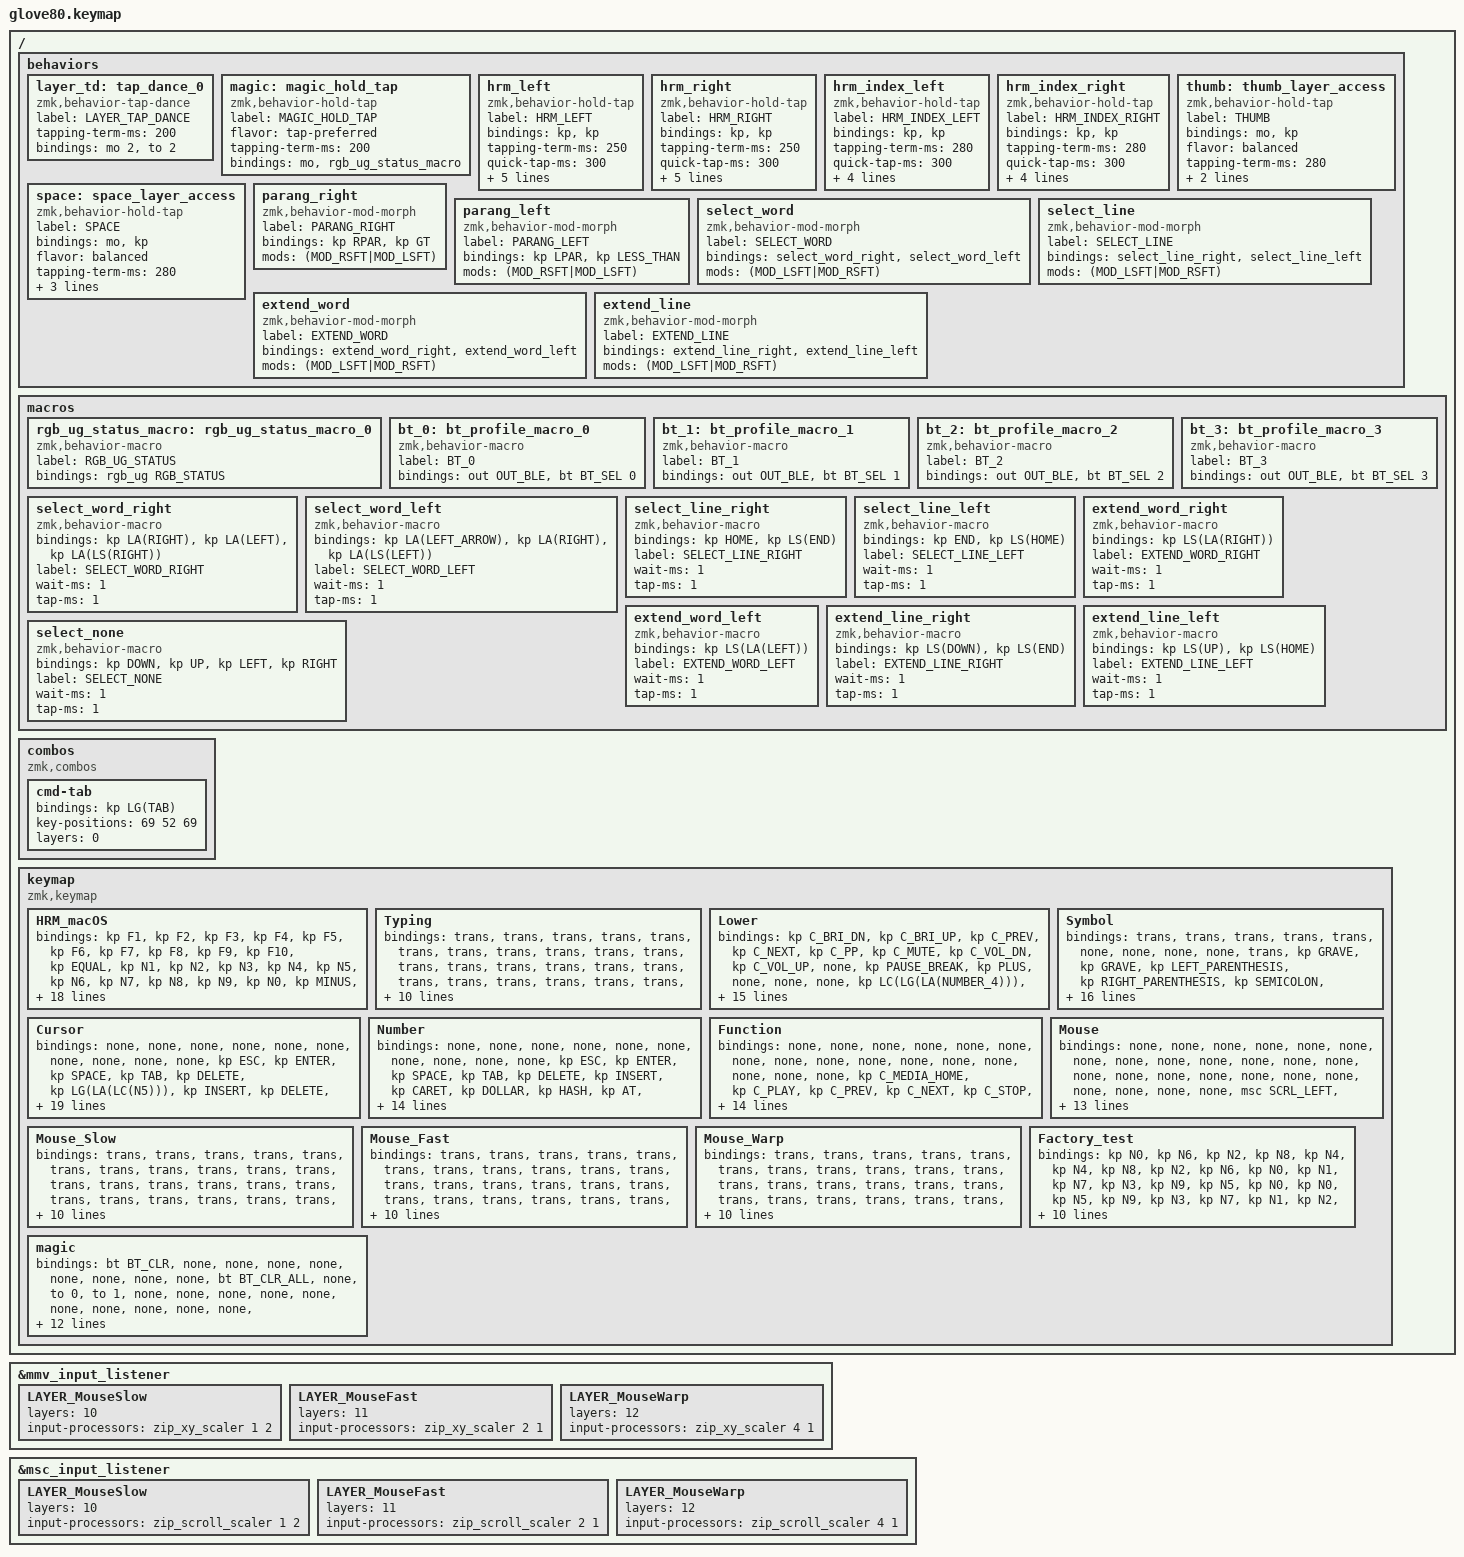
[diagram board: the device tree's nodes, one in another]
/*
 * Copyright (c) 2020 The ZMK Contributors
 *
 * SPDX-License-Identifier: MIT
 */

#include <input/processors.dtsi>
#include <behaviors.dtsi>
#include <dt-bindings/zmk/bt.h>
#include <dt-bindings/zmk/keys.h>
#include <dt-bindings/zmk/outputs.h>
#include <dt-bindings/zmk/pointing.h>
#include <dt-bindings/zmk/rgb.h>

#define HYPER LC(LS(LG(LALT)))

// layers

#define DEFAULT 0
#define LOWER 1
#define MAGIC 2
#define FACTORY_TEST 3
#define LAYER_MouseSlow 10
#define LAYER_MouseFast 11
#define LAYER_MouseWarp 12

/* Input Listeners */

&mmv_input_listener {
    // LAYER_MouseSlow
    // 

    LAYER_MouseSlow {
        layers = <10>;
        input-processors = <&zip_xy_scaler 1 2>;
    };

    // LAYER_MouseFast

    LAYER_MouseFast {
        layers = <11>;
        input-processors = <&zip_xy_scaler 2 1>;
    };

    // LAYER_MouseWarp

    LAYER_MouseWarp {
        layers = <12>;
        input-processors = <&zip_xy_scaler 4 1>;
    };
};

&msc_input_listener {
    // LAYER_MouseSlow
    // 

    LAYER_MouseSlow {
        layers = <10>;
        input-processors = <&zip_scroll_scaler 1 2>;
    };

    // LAYER_MouseFast

    LAYER_MouseFast {
        layers = <11>;
        input-processors = <&zip_scroll_scaler 2 1>;
    };

    // LAYER_MouseWarp

    LAYER_MouseWarp {
        layers = <12>;
        input-processors = <&zip_scroll_scaler 4 1>;
    };
};

/ {
    behaviors {
        // For the "layer" key, it'd nice to be able to use it as either a shift or a toggle.
        // Configure it as a tap dance, so the first tap (or hold) is a &mo and the second tap is a &to

        layer_td: tap_dance_0 {
            compatible = "zmk,behavior-tap-dance";
            label = "LAYER_TAP_DANCE";
            #binding-cells = <0>;
            tapping-term-ms = <200>;
            bindings = <&mo 2>, <&to 2>;
        };

        magic: magic_hold_tap {
            compatible = "zmk,behavior-hold-tap";
            label = "MAGIC_HOLD_TAP";
            #binding-cells = <2>;
            flavor = "tap-preferred";
            tapping-term-ms = <200>;
            bindings = <&mo>, <&rgb_ug_status_macro>;
        };

        hrm_left: hrm_left {
            compatible = "zmk,behavior-hold-tap";
            label = "HRM_LEFT";
            bindings = <&kp>, <&kp>;

            #binding-cells = <2>;
            tapping-term-ms = <250>;
            quick-tap-ms = <300>;
            flavor = "tap-preferred";
            hold-trigger-on-release;
            hold-trigger-key-positions = <5 6 7 8 9 16 17 18 19 20 21 28 29 30 31 32 33 40 41 42 43 44 45 55 56 57 58 59 60 61 62 63 72 73 74 75 76 77 78 79 52 53 54 69 70 71>;
            require-prior-idle-ms = <250>;
        };

        hrm_right: hrm_right {
            compatible = "zmk,behavior-hold-tap";
            label = "HRM_RIGHT";
            bindings = <&kp>, <&kp>;

            #binding-cells = <2>;
            tapping-term-ms = <250>;
            quick-tap-ms = <300>;
            flavor = "tap-preferred";
            hold-trigger-on-release;
            hold-trigger-key-positions = <0 1 2 3 4 10 11 12 13 14 15 22 23 24 25 26 27 34 35 36 37 38 39 46 47 48 49 50 51 52 53 54 55 56 57 64 65 66 67 68 69 70 71 72 73 74>;
            require-prior-idle-ms = <250>;
        };

        hrm_index_left: hrm_index_left {
            compatible = "zmk,behavior-hold-tap";
            label = "HRM_INDEX_LEFT";
            bindings = <&kp>, <&kp>;

            #binding-cells = <2>;
            tapping-term-ms = <280>;
            quick-tap-ms = <300>;
            flavor = "tap-preferred";
            hold-trigger-key-positions = <5 6 7 8 9 16 17 18 19 20 21 28 29 30 31 32 33 40 41 42 43 44 45 55 56 57 58 59 60 61 62 63 72 73 74 75 76 77 78 79 52 53 54 69 70 71>;
            require-prior-idle-ms = <250>;
        };

        hrm_index_right: hrm_index_right {
            compatible = "zmk,behavior-hold-tap";
            label = "HRM_INDEX_RIGHT";
            bindings = <&kp>, <&kp>;

            #binding-cells = <2>;
            tapping-term-ms = <280>;
            quick-tap-ms = <300>;
            flavor = "tap-preferred";
            hold-trigger-key-positions = <0 1 2 3 4 10 11 12 13 14 15 22 23 24 25 26 27 34 35 36 37 38 39 46 47 48 49 50 51 52 53 54 55 56 57 64 65 66 67 68 69 70 71 72 73 74>;
            require-prior-idle-ms = <250>;
        };

        thumb: thumb_layer_access {
            compatible = "zmk,behavior-hold-tap";
            label = "THUMB";
            bindings = <&mo>, <&kp>;

            #binding-cells = <2>;
            flavor = "balanced";
            tapping-term-ms = <280>;
            quick-tap-ms = <110>;
            require-prior-idle-ms = <170>;
        };

        space: space_layer_access {
            compatible = "zmk,behavior-hold-tap";
            label = "SPACE";
            bindings = <&mo>, <&kp>;

            #binding-cells = <2>;
            flavor = "balanced";
            tapping-term-ms = <280>;
            quick-tap-ms = <175>;
            require-prior-idle-ms = <170>;
            hold-trigger-on-release;
        };

        parang_right: parang_right {
            compatible = "zmk,behavior-mod-morph";
            label = "PARANG_RIGHT";
            bindings = <&kp RPAR>, <&kp GT>;

            #binding-cells = <0>;
            mods = <(MOD_RSFT|MOD_LSFT)>;
        };

        parang_left: parang_left {
            compatible = "zmk,behavior-mod-morph";
            label = "PARANG_LEFT";
            bindings = <&kp LPAR>, <&kp LESS_THAN>;

            #binding-cells = <0>;
            mods = <(MOD_RSFT|MOD_LSFT)>;
        };

        select_word: select_word {
            compatible = "zmk,behavior-mod-morph";
            label = "SELECT_WORD";
            #binding-cells = <0>;
            bindings = <&select_word_right>, <&select_word_left>;

            mods = <(MOD_LSFT|MOD_RSFT)>;
        };

        select_line: select_line {
            compatible = "zmk,behavior-mod-morph";
            label = "SELECT_LINE";
            bindings = <&select_line_right>, <&select_line_left>;

            #binding-cells = <0>;
            mods = <(MOD_LSFT|MOD_RSFT)>;
        };

        extend_word: extend_word {
            compatible = "zmk,behavior-mod-morph";
            label = "EXTEND_WORD";
            bindings = <&extend_word_right>, <&extend_word_left>;

            #binding-cells = <0>;
            mods = <(MOD_LSFT|MOD_RSFT)>;
        };

        extend_line: extend_line {
            compatible = "zmk,behavior-mod-morph";
            label = "EXTEND_LINE";
            bindings = <&extend_line_right>, <&extend_line_left>;

            #binding-cells = <0>;
            mods = <(MOD_LSFT|MOD_RSFT)>;
        };
    };

    macros {
        rgb_ug_status_macro: rgb_ug_status_macro_0 {
            label = "RGB_UG_STATUS";
            compatible = "zmk,behavior-macro";
            #binding-cells = <0>;
            bindings = <&rgb_ug RGB_STATUS>;
        };

        bt_0: bt_profile_macro_0 {
            label = "BT_0";
            compatible = "zmk,behavior-macro";
            #binding-cells = <0>;
            bindings = <&out OUT_BLE &bt BT_SEL 0>;
        };

        bt_1: bt_profile_macro_1 {
            label = "BT_1";
            compatible = "zmk,behavior-macro";
            #binding-cells = <0>;
            bindings = <&out OUT_BLE &bt BT_SEL 1>;
        };

        bt_2: bt_profile_macro_2 {
            label = "BT_2";
            compatible = "zmk,behavior-macro";
            #binding-cells = <0>;
            bindings = <&out OUT_BLE &bt BT_SEL 2>;
        };

        bt_3: bt_profile_macro_3 {
            label = "BT_3";
            compatible = "zmk,behavior-macro";
            #binding-cells = <0>;
            bindings = <&out OUT_BLE &bt BT_SEL 3>;
        };

        select_word_right: select_word_right {
            compatible = "zmk,behavior-macro";
            #binding-cells = <0>;
            bindings = <&kp LA(RIGHT) &kp LA(LEFT) &kp LA(LS(RIGHT))>;
            label = "SELECT_WORD_RIGHT";
            wait-ms = <1>;
            tap-ms = <1>;
        };

        select_word_left: select_word_left {
            compatible = "zmk,behavior-macro";
            #binding-cells = <0>;
            bindings = <&kp LA(LEFT_ARROW) &kp LA(RIGHT) &kp LA(LS(LEFT))>;
            label = "SELECT_WORD_LEFT";
            wait-ms = <1>;
            tap-ms = <1>;
        };

        select_line_right: select_line_right {
            compatible = "zmk,behavior-macro";
            #binding-cells = <0>;
            bindings = <&kp HOME &kp LS(END)>;
            label = "SELECT_LINE_RIGHT";
            wait-ms = <1>;
            tap-ms = <1>;
        };

        select_line_left: select_line_left {
            compatible = "zmk,behavior-macro";
            #binding-cells = <0>;
            bindings = <&kp END &kp LS(HOME)>;
            label = "SELECT_LINE_LEFT";
            wait-ms = <1>;
            tap-ms = <1>;
        };

        extend_word_right: extend_word_right {
            compatible = "zmk,behavior-macro";
            #binding-cells = <0>;
            bindings = <&kp LS(LA(RIGHT))>;
            label = "EXTEND_WORD_RIGHT";
            wait-ms = <1>;
            tap-ms = <1>;
        };

        extend_word_left: extend_word_left {
            compatible = "zmk,behavior-macro";
            #binding-cells = <0>;
            bindings = <&kp LS(LA(LEFT))>;
            label = "EXTEND_WORD_LEFT";
            wait-ms = <1>;
            tap-ms = <1>;
        };

        extend_line_right: extend_line_right {
            compatible = "zmk,behavior-macro";
            #binding-cells = <0>;
            bindings = <&kp LS(DOWN) &kp LS(END)>;
            label = "EXTEND_LINE_RIGHT";
            wait-ms = <1>;
            tap-ms = <1>;
        };

        extend_line_left: extend_line_left {
            compatible = "zmk,behavior-macro";
            #binding-cells = <0>;
            bindings = <&kp LS(UP) &kp LS(HOME)>;
            label = "EXTEND_LINE_LEFT";
            wait-ms = <1>;
            tap-ms = <1>;
        };

        select_none: select_none {
            compatible = "zmk,behavior-macro";
            #binding-cells = <0>;
            bindings = <&kp DOWN &kp UP &kp LEFT &kp RIGHT>;
            label = "SELECT_NONE";
            wait-ms = <1>;
            tap-ms = <1>;
        };
    };

    combos {
        compatible = "zmk,combos";

        cmd-tab {
            bindings = <&kp LG(TAB)>;
            key-positions = <69 52 69>;
            layers = <0>;
        };
    };

    keymap {
        compatible = "zmk,keymap";

        HRM_macOS {
            // ---------------------------------------------------------------------------------------------------------------------------------
            // |  F1   |  F2 |  F3 |  F4  |  F5  |                                                               |  F6   |  F7   |  F8  |   F9  |  F10 |
            // |  =    |  1  |  2  |  3   |  4   |  5   |                                                 |  6   |   7   |   8   |  9   |   0   |   -  |
            // |  TAB  |  Q  |  W  |  E   |  R   |  T   |                                                 |  Y   |   U   |   I   |  O   |   P   |   \  |
            // |  ESC  |  A  |  S  |  D   |  F   |  G   |                                                 |  H   |   J   |   K   |  L   |   ;   |   '  |
            // |   `   |  Z  |  X  |  C   |  V   |  B   | LSHFT | LCTRL | LOWER | | LGUI  | RCTRL | RSHFT |  N   |   M   |   ,   |  .   |   /   | PGUP |
            // | MAGIC | HOME| END | LEFT | RIGHT|      | BSPC  | DEL   | LALT  | | RALT  | RET   | SPACE |      |  UP   | DOWN  |  [   |   ]   | PGDN |

            bindings = <
&kp F1       &kp F2             &kp F3             &kp F4             &kp F5                                                                                                                                                                              &kp F6                    &kp F7             &kp F8             &kp F9                      &kp F10
&kp EQUAL    &kp N1             &kp N2             &kp N3             &kp N4                   &kp N5                                                                                                                        &kp N6                       &kp N7                    &kp N8             &kp N9             &kp N0                      &kp MINUS
&kp TAB      &kp Q              &kp W              &kp E              &kp R                    &kp T                                                                                                                         &kp Y                        &kp U                     &kp I              &kp O              &kp P                       &kp BSLH
&kp ESCAPE   &hrm_left LCTRL A  &hrm_right LALT S  &hrm_left LGUI D   &hrm_index_left LSHFT F  &kp G                                                                                                                         &kp H                        &hrm_index_right RSHFT J  &hrm_right RGUI K  &hrm_right LALT L  &hrm_right RCTRL SEMICOLON  &kp SQT
&kp GRAVE    &kp Z              &kp X              &kp C              &kp V                    &hrm_left LC(LEFT_ALT) B  &thumb 6 ESCAPE     &caps_word       &layer_td       &layer_td      &kp CAPS        &kp ENTER       &hrm_right RA(LEFT_SHIFT) N  &kp M                     &kp COMMA          &kp DOT            &kp FSLH                    &kp PAGE_UP
&magic 12 0  &parang_left       &kp LEFT_BRACKET   &kp RIGHT_BRACKET  &parang_right                                      &thumb 4 BACKSPACE  &thumb 5 DELETE  &thumb 2 LG(S)  &kp BACKSPACE  &thumb 7 ENTER  &space 3 SPACE                               &kp LEFT                  &kp DOWN           &kp UP_ARROW       &kp RIGHT                   &kp PAGE_DOWN
            >;
        };

        Typing {
            bindings = <
&trans  &trans  &trans  &trans  &trans                                                                  &trans  &trans  &trans  &trans         &trans
&trans  &trans  &trans  &trans  &trans  &trans                                                  &trans  &trans  &trans  &trans  &trans         &trans
&trans  &trans  &trans  &trans  &trans  &trans                                                  &trans  &trans  &trans  &trans  &trans         &trans
&trans  &kp A   &kp S   &kp D   &kp F   &trans                                                  &trans  &kp J   &kp K   &kp L   &kp SEMICOLON  &trans
&trans  &trans  &trans  &trans  &trans  &trans  &trans  &trans  &trans  &trans  &trans  &trans  &trans  &trans  &trans  &trans  &trans         &trans
&trans  &trans  &trans  &trans  &trans          &trans  &trans  &trans  &trans  &trans  &trans          &trans  &trans  &trans  &trans         &trans
            >;
        };

        Lower {
            bindings = <
&kp C_BRI_DN  &kp C_BRI_UP  &kp C_PREV  &kp C_NEXT  &kp C_PP                                                                                              &kp C_MUTE  &kp C_VOL_DN  &kp C_VOL_UP   &none            &kp PAUSE_BREAK
&kp PLUS      &none         &none       &none       &kp LC(LG(LA(NUMBER_4)))  &kp LG(LA(LC(N5)))                                               &kp LPAR   &kp KP_NUM  &kp KP_EQUAL  &kp KP_DIVIDE  &kp KP_MULTIPLY  &kp PSCRN
&kp TAB       &none         &none       &kp UP      &none                     &kp LS(LA(LG(LC(D))))                                            &kp RPAR   &kp KP_N7   &kp KP_N8     &kp KP_N9      &kp KP_MINUS     &kp SLCK
&kp ESCAPE    &none         &kp LEFT    &kp DOWN    &kp RIGHT                 &none                                                            &kp PRCNT  &kp KP_N4   &kp KP_N5     &kp KP_N6      &kp KP_PLUS      &none
&kp TILDE     &kp K_CMENU   &kp F1      &kp F2      &kp F5                    &none                  &to 6  &none  &none  &none  &none  &none  &kp COMMA  &kp KP_N1   &kp KP_N2     &kp KP_N3      &kp KP_ENTER     &trans
&trans        &kp CAPS      &kp F10     &kp F11     &kp F12                                          &to 4  &to 5  &none  &none  &to 7  &to 3             &kp KP_N0   &kp KP_N0     &kp KP_DOT     &kp KP_ENTER     &trans
            >;
        };

        Symbol {
            bindings = <
&trans           &trans         &trans                &trans                 &trans                                                                                                    &none          &none        &none          &none          &trans
&kp GRAVE        &kp GRAVE      &kp LEFT_PARENTHESIS  &kp RIGHT_PARENTHESIS  &kp SEMICOLON     &kp COMMA                                                                &none          &none          &none        &none          &none          &none
&kp EXCLAMATION  &kp LBRC       &kp SQT               &kp DOUBLE_QUOTES      &kp RBRC          &kp QUESTION                                                             &kp SEMICOLON  &kp RSHFT      &kp RGUI     &kp RALT       &kp RCTRL      &none
&kp HASH         &kp CARET      &kp EQUAL             &kp UNDERSCORE         &kp DOLLAR        &kp ASTERISK                                                             &kp DOT        &kp BACKSPACE  &kp TAB      &kp SPACE      &kp ENTER      &none
&kp AT           &kp LESS_THAN  &kp PIPE              &kp MINUS              &kp GREATER_THAN  &kp FSLH      &kp BSLH     &kp DOT    &kp ASTERISK  &to 0  &none  &none  &kp RG(SPACE)  &kp DEL        &kp LS(TAB)  &kp RC(SPACE)  &kp RA(ENTER)  &none
&kp TILDE        &kp AMPERSAND  &kp LBKT              &kp RBKT               &kp PLUS                        &kp PERCENT  &kp COLON  &kp SEMI      &none  &none  &none                 &trans         &trans       &trans         &trans         &kp RG(SPACE)
            >;
        };

        Cursor {
            bindings = <
&none           &none            &none          &none         &none                                                                                                                                 &none          &none            &none          &none            &none
&kp ESC         &kp ENTER        &kp SPACE      &kp TAB       &kp DELETE     &kp LG(LA(LC(N5)))                                                                                         &kp INSERT  &kp DELETE     &kp TAB          &kp SPACE      &kp ENTER        &kp ESC
&kp CAPSLOCK    &sk RIGHT_SHIFT  &kp LG(LS(Z))  &kp LG(Z)     &kp BACKSPACE  &kp LG(X)                                                                                                  &kp RG(X)   &kp BACKSPACE  &kp RG(Z)        &kp RG(RS(Z))  &sk RIGHT_SHIFT  &kp RG(K)
&sk LEFT_SHIFT  &kp LCTRL        &kp LALT       &kp LGUI      &kp LSHFT      &kp LG(C)                                                                                                  &kp LEFT    &kp DOWN       &kp UP_ARROW     &kp RIGHT      &none            &kp RG(L)
&kp LG(J)       &kp LG(A)        &select_line   &select_word  &kp LG(F)      &kp LG(V)           &kp LS(LA(LG(V)))  &kp LC(TAB)  &to 0        &select_none  &extend_line  &extend_word  &kp HOME    &kp PAGE_DOWN  &kp RG(PAGE_UP)  &kp END        &kp LA(RG(F))    &kp RG(J)
&kp LA(LG(F))   &kp LG(LS(G))    &extend_line   &extend_word  &kp LG(G)                          &none              &kp LG(TAB)  &kp LA(TAB)  &kp RG(A)     &select_line  &select_word              &kp HOME       &kp PAGE_DOWN    &kp PG_UP      &kp END          &kp RC(RG(SPACE))
            >;
        };

        Number {
            bindings = <
&none           &none      &none          &none         &none                                                                                                     &none       &none     &none   &none            &none
&kp ESC         &kp ENTER  &kp SPACE      &kp TAB       &kp DELETE     &kp INSERT                                                                   &kp CARET     &kp DOLLAR  &kp HASH  &kp AT  &kp EXCLAMATION  &kp PIPE
&none           &sk LSHFT  &kp LG(LS(Z))  &kp LG(Z)     &kp BACKSPACE  &kp A                                                                        &kp PERCENT   &kp N7      &kp N8    &kp N9  &kp COLON        &kp K
&kp LG(ESCAPE)  &kp LCTRL  &kp LALT       &kp LGUI      &kp LSHIFT     &kp B                                                                        &kp PLUS      &kp N4      &kp N5    &kp N6  &kp MINUS        &kp J
&none           &kp LG(A)  &select_line   &select_word  &kp BACKSPACE  &kp D       &kp E  &kp F  &to 0  &kp LESS_THAN  &kp GREATER_THAN  &kp EQUAL  &kp ASTERISK  &kp N1      &kp N2    &kp N3  &kp FSLH         &kp RS(G)
&none           &none      &extend_line   &extend_word  &kp DELETE                 &none  &none  &none  &kp COMMA      &kp DOT           &kp N0                   &trans      &trans    &trans  &trans           &kp TILDE
            >;
        };

        Function {
            bindings = <
&none     &none      &none     &none     &none                                                                                                     &none                     &none                 &none                 &none                     &none
&none     &none      &none     &none     &none      &none                                                                        &kp C_MEDIA_HOME  &kp C_PLAY                &kp C_PREV            &kp C_NEXT            &kp C_STOP                &kp C_EJECT
&none     &none      &none     &none     &none      &none                                                                        &kp K_WWW         &kp F7                    &kp F8                &kp F9                &kp F10                   &kp F13
&kp CAPS  &kp LCTRL  &kp LALT  &kp LGUI  &kp LSHFT  &none                                                                        &kp K_CALC        &kp F4                    &kp F5                &kp F6                &kp F11                   &kp F14
&none     &none      &none     &none     &none      &none  &none  &none  &to 0  &kp C_PREV  &kp C_NEXT         &kp C_PLAY_PAUSE  &kp C_AL_FILES    &kp F1                    &kp F2                &kp F3                &kp F12                   &kp F15
&none     &none      &none     &none     &none             &none  &none  &none  &kp C_MUTE  &kp C_VOLUME_DOWN  &kp C_VOLUME_UP                     &kp C_BRIGHTNESS_MINIMUM  &kp C_BRIGHTNESS_INC  &kp C_BRIGHTNESS_DEC  &kp C_BRIGHTNESS_MINIMUM  &kp C_BRIGHTNESS_AUTO
            >;
        };

        Mouse {
            bindings = <
&none  &none           &none           &none           &none                                                                                                 &none           &none           &none            &none      &none
&none  &none           &none           &none           &none            &none                                                                &none           &none           &none           &none            &none      &none
&none  &none           &msc SCRL_LEFT  &mmv MOVE_UP    &msc SCRL_RIGHT  &none                                                                &none           &sk RSHFT       &sk RGUI        &sk RALT         &sk RCTRL  &none
&none  &msc SCRL_UP    &mmv MOVE_LEFT  &mmv MOVE_DOWN  &mmv MOVE_RIGHT  &msc SCRL_UP                                                         &msc SCRL_UP    &mo 9           &mo 10          &mo 8            &mkp LCLK  &mkp MB4
&none  &msc SCRL_DOWN  &mo 8           &mo 10          &mo 9            &msc SCRL_DOWN  &mkp MCLK  &kp K_APP  &mkp MB5  &to 0  &none  &none  &msc SCRL_DOWN  &msc SCRL_LEFT  &mmv MOVE_UP    &msc SCRL_RIGHT  &mkp RCLK  &mkp MB5
&none  &none           &none           &none           &none                            &mkp LCLK  &mkp RCLK  &mkp MB4  &none  &none  &none                  &mmv MOVE_LEFT  &mmv MOVE_DOWN  &mmv MOVE_RIGHT  &mkp MCLK  &kp K_APP
            >;
        };

        Mouse_Slow {
            bindings = <
&trans  &trans  &trans  &trans  &trans                                                                  &trans  &trans  &trans  &trans  &trans
&trans  &trans  &trans  &trans  &trans  &trans                                                  &trans  &trans  &trans  &trans  &trans  &trans
&trans  &trans  &trans  &trans  &trans  &trans                                                  &trans  &trans  &trans  &trans  &trans  &trans
&trans  &trans  &trans  &trans  &trans  &trans                                                  &trans  &trans  &trans  &trans  &trans  &trans
&trans  &trans  &trans  &trans  &trans  &trans  &trans  &trans  &trans  &trans  &trans  &trans  &trans  &trans  &trans  &trans  &trans  &trans
&trans  &trans  &trans  &trans  &trans          &trans  &trans  &trans  &trans  &trans  &trans          &trans  &trans  &trans  &trans  &trans
            >;
        };

        Mouse_Fast {
            bindings = <
&trans  &trans  &trans  &trans  &trans                                                                  &trans  &trans  &trans  &trans  &trans
&trans  &trans  &trans  &trans  &trans  &trans                                                  &trans  &trans  &trans  &trans  &trans  &trans
&trans  &trans  &trans  &trans  &trans  &trans                                                  &trans  &trans  &trans  &trans  &trans  &trans
&trans  &trans  &trans  &trans  &trans  &trans                                                  &trans  &trans  &trans  &trans  &trans  &trans
&trans  &trans  &trans  &trans  &trans  &trans  &trans  &trans  &trans  &trans  &trans  &trans  &trans  &trans  &trans  &trans  &trans  &trans
&trans  &trans  &trans  &trans  &trans          &trans  &trans  &trans  &trans  &trans  &trans          &trans  &trans  &trans  &trans  &trans
            >;
        };

        Mouse_Warp {
            bindings = <
&trans  &trans  &trans  &trans  &trans                                                                  &trans  &trans  &trans  &trans  &trans
&trans  &trans  &trans  &trans  &trans  &trans                                                  &trans  &trans  &trans  &trans  &trans  &trans
&trans  &trans  &trans  &trans  &trans  &trans                                                  &trans  &trans  &trans  &trans  &trans  &trans
&trans  &trans  &trans  &trans  &trans  &trans                                                  &trans  &trans  &trans  &trans  &trans  &trans
&trans  &trans  &trans  &trans  &trans  &trans  &trans  &trans  &trans  &trans  &trans  &trans  &trans  &trans  &trans  &trans  &trans  &trans
&trans  &trans  &trans  &trans  &trans          &trans  &trans  &trans  &trans  &trans  &trans          &trans  &trans  &trans  &trans  &trans
            >;
        };

        Factory_test {
            bindings = <
&kp N0  &kp N6  &kp N2  &kp N8  &kp N4                                                                  &kp N4  &kp N8  &kp N2  &kp N6  &kp N0
&kp N1  &kp N7  &kp N3  &kp N9  &kp N5  &kp N0                                                  &kp N0  &kp N5  &kp N9  &kp N3  &kp N7  &kp N1
&kp N2  &kp N8  &kp N4  &kp N0  &kp N6  &kp N1                                                  &kp N1  &kp N6  &kp N0  &kp N4  &kp N8  &kp N2
&kp N3  &kp N9  &kp N5  &kp N1  &kp N7  &kp N2                                                  &kp N2  &kp N7  &kp N1  &kp N5  &kp N9  &kp N3
&kp N4  &kp N0  &kp N6  &kp N2  &kp N8  &kp N3  &kp N4  &kp N5  &kp N6  &kp N6  &kp N5  &kp N4  &kp N3  &kp N8  &kp N2  &kp N6  &kp N0  &kp N4
&kp N5  &kp N1  &kp N7  &kp N3  &kp N9          &kp N7  &kp N8  &kp N9  &kp N9  &kp N8  &kp N7          &kp N9  &kp N3  &kp N7  &kp N1  &kp N5
            >;
        };

        magic {
            bindings = <
&bt BT_CLR   &none            &none            &none            &none                                                                                     &none  &none  &none  &none  &bt BT_CLR_ALL
&none        &to 0            &to 1            &none            &none            &none                                                             &none  &none  &none  &none  &none  &none
&none        &rgb_ug RGB_SPI  &rgb_ug RGB_SAI  &rgb_ug RGB_HUI  &rgb_ug RGB_BRI  &rgb_ug RGB_TOG                                                   &none  &none  &none  &none  &none  &none
&bootloader  &rgb_ug RGB_SPD  &rgb_ug RGB_SAD  &rgb_ug RGB_HUD  &rgb_ug RGB_BRD  &rgb_ug RGB_EFF                                                   &none  &none  &none  &none  &none  &bootloader
&sys_reset   &none            &none            &none            &none            &none            &bt_2  &bt_3  &none         &none  &none  &none  &none  &none  &none  &none  &none  &sys_reset
&none        &none            &none            &none            &none                             &bt_0  &bt_1  &out OUT_USB  &none  &none  &none         &none  &none  &none  &none  &to 11
            >;
        };
    };
};
